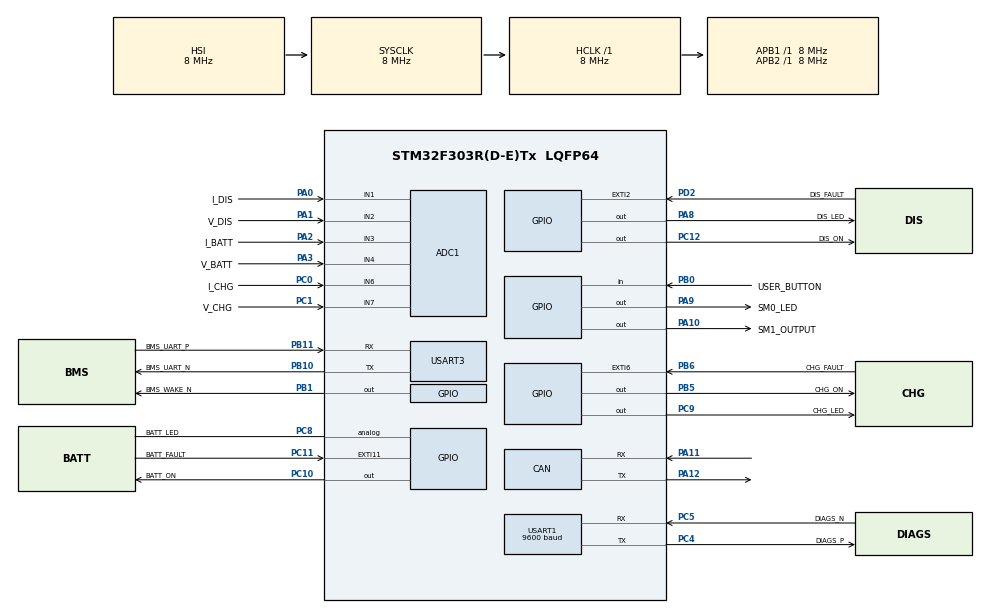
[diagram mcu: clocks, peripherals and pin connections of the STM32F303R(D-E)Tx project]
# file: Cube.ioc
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ADC1.Channel-3\#ChannelRegularConversion=ADC_CHANNEL_1
ADC1.NbrOfConversionFlag=1
ADC1.Offset-3\#ChannelRegularConversion=0
ADC1.OffsetNumber-3\#ChannelRegularConversion=ADC_OFFSET_NONE
ADC1.Rank-3\#ChannelRegularConversion=1
ADC1.SamplingTime-3\#ChannelRegularConversion=ADC_SAMPLETIME_1CYCLE_5
ADC1.master=1
CAN.CalculateTimeQuantum=2000.0
Mcu.Family=STM32F3
Mcu.Name=STM32F303R(D-E)Tx
Mcu.Package=LQFP64
NVIC.PriorityGroup=NVIC_PRIORITYGROUP_4
PA0.GPIO_Label=I_DIS
PA0.Mode=IN1-Single-Ended
PA0.Signal=ADC1_IN1
PA1.GPIO_Label=V_DIS
PA1.Mode=IN2-Single-Ended
PA1.Signal=ADC1_IN2
PA10.GPIO_Label=SM1_OUTPUT
PA10.Signal=GPIO_Output
PA11.Mode=Master
PA11.Signal=CAN_RX
PA12.Mode=Master
PA12.Signal=CAN_TX
PA13.Mode=JTAG_5_pins
PA13.Signal=SYS_JTMS-SWDIO
PA14.Mode=JTAG_5_pins
PA14.Signal=SYS_JTCK-SWCLK
PA15.Mode=JTAG_5_pins
PA15.Signal=SYS_JTDI
PA2.GPIO_Label=I_BATT
PA2.Mode=IN3-Single-Ended
PA2.Signal=ADC1_IN3
PA3.GPIO_Label=V_BATT
PA3.Mode=IN4-Single-Ended
PA3.Signal=ADC1_IN4
PA8.GPIO_Label=DIS_LED
PA8.Signal=GPIO_Output
PA9.GPIO_Label=SM0_LED
PA9.Signal=GPIO_Output
PB0.GPIO_Label=USER_BUTTON
PB0.Signal=GPIO_Input
PB1.GPIO_Label=BMS_WAKE_N
PB1.Signal=GPIO_Output
PB10.GPIO_Label=BMS_UART_N
PB10.Mode=Asynchronous
PB10.Signal=USART3_TX
PB11.GPIO_Label=BMS_UART_P
PB11.Mode=Asynchronous
PB11.Signal=USART3_RX
PB3.Mode=JTAG_5_pins
PB3.Signal=SYS_JTDO-TRACESWO
PB4.Mode=JTAG_5_pins
PB4.Signal=SYS_NJTRST
PB5.GPIO_Label=CHG_ON
PB5.Signal=GPIO_Output
PB6.GPIO_Label=CHG_FAULT
PB6.Signal=GPXTI6
PC0.GPIO_Label=I_CHG
PC0.Signal=ADCx_IN6
PC1.GPIO_Label=V_CHG
PC1.Signal=ADCx_IN7
PC10.GPIO_Label=BATT_ON
PC10.Signal=GPIO_Output
PC11.GPIO_Label=BATT_FAULT
PC11.Signal=GPXTI11
PC12.GPIO_Label=DIS_ON
PC12.Signal=GPIO_Output
PC14-OSC32_IN.Mode=LSE-External-Oscillator
PC14-OSC32_IN.Signal=RCC_OSC32_IN
PC15-OSC32_OUT.Mode=LSE-External-Oscillator
PC15-OSC32_OUT.Signal=RCC_OSC32_OUT
PC4.GPIO_Label=DIAGS_P
PC4.Mode=Asynchronous
PC4.Signal=USART1_TX
PC5.GPIO_Label=DIAGS_N
PC5.Mode=Asynchronous
PC5.Signal=USART1_RX
PC8.GPIO_Label=BATT_LED
PC8.Signal=GPIO_Analog
PC9.GPIO_Label=CHG_LED
PC9.Signal=GPIO_Output
PD2.GPIO_Label=DIS_FAULT
PD2.Signal=GPXTI2
PF0-OSC_IN.Mode=HSE-External-Oscillator
PF0-OSC_IN.Signal=RCC_OSC_IN
PF1-OSC_OUT.Mode=HSE-External-Oscillator
PF1-OSC_OUT.Signal=RCC_OSC_OUT
ProjectManager.HeapSize=0x200
ProjectManager.StackSize=0x400
ProjectManager.TargetToolchain=SW4STM32
RCC.AHBFreq_Value=8000000
RCC.APB1Freq_Value=8000000
RCC.APB2Freq_Value=8000000
RCC.CortexFreq_Value=8000000
RCC.HSE_VALUE=16000000
RCC.HSI_VALUE=8000000
RCC.SYSCLKFreq_VALUE=8000000
RCC.USBFreq_Value=16000000
SH.ADCx_IN6.0=ADC1_IN6,IN6-Single-Ended
SH.ADCx_IN7.0=ADC1_IN7,IN7-Single-Ended
USART1.BaudRate=9600
USART1.VirtualMode-Asynchronous=VM_ASYNC
USART3.VirtualMode-Asynchronous=VM_ASYNC
board=custom

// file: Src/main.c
/* USER CODE BEGIN Header */
/**
  ******************************************************************************
  * @file           : main.c
  * @brief          : Main program body
  ******************************************************************************
  * @attention
  *
  * <h2><center>&copy; Copyright (c) 2020 STMicroelectronics.
  * All rights reserved.</center></h2>
  *
  * This software component is licensed by ST under BSD 3-Clause license,
  * the "License"; You may not use this file except in compliance with the
  * License. You may obtain a copy of the License at:
  *                        opensource.org/licenses/BSD-3-Clause
  *
  ******************************************************************************
  */
/* USER CODE END Header */

#include "main.h"

ADC_HandleTypeDef hadc1;

CAN_HandleTypeDef hcan;

UART_HandleTypeDef huart1;
UART_HandleTypeDef huart3;

void SystemClock_Config(void);
static void MX_GPIO_Init(void);
static void MX_CAN_Init(void);
static void MX_USART1_UART_Init(void);
static void MX_USART3_UART_Init(void);
static void MX_ADC1_Init(void);

int main(void)
{

  /* MCU Configuration--------------------------------------------------------*/

  /* Reset of all peripherals, Initializes the Flash interface and the Systick. */
  HAL_Init();

  /* Configure the system clock */
  SystemClock_Config();

  /* Initialize all configured peripherals */
  MX_GPIO_Init();
  MX_CAN_Init();
  MX_USART1_UART_Init();
  MX_USART3_UART_Init();
  MX_ADC1_Init();

  /* USER CODE BEGIN 2 */
  diagsUARTInit(&huart1);

  /* USER CODE END 2 */

  /* Infinite loop */
  /* USER CODE BEGIN WHILE */
  while (1)
  {
    //HAL_GPIO_TogglePin(GPIOC, CHG_LED_Pin);
    //HAL_GPIO_TogglePin(GPIOA, SM0_LED_Pin);
    //HAL_GPIO_TogglePin(GPIOA, SM1_OUTPUT_Pin);
	debugToggleLED(GPIOA, SM0_LED_Pin);
	debugPrintLine("tiddies");
    HAL_Delay(1400);
  }
  /* USER CODE END 3 */
}

void SystemClock_Config(void)
{
  RCC_OscInitTypeDef RCC_OscInitStruct = {0};
  RCC_ClkInitTypeDef RCC_ClkInitStruct = {0};
  RCC_PeriphCLKInitTypeDef PeriphClkInit = {0};

  /** Initializes the CPU, AHB and APB busses clocks
  */
  RCC_OscInitStruct.OscillatorType = RCC_OSCILLATORTYPE_HSI;
  RCC_OscInitStruct.HSIState = RCC_HSI_ON;
  RCC_OscInitStruct.HSICalibrationValue = RCC_HSICALIBRATION_DEFAULT;
  RCC_OscInitStruct.PLL.PLLState = RCC_PLL_ON;
  RCC_OscInitStruct.PLL.PLLSource = RCC_PLLSOURCE_HSI;
  RCC_OscInitStruct.PLL.PLLMUL = RCC_PLL_MUL2;
  RCC_OscInitStruct.PLL.PREDIV = RCC_PREDIV_DIV1;
  if (HAL_RCC_OscConfig(&RCC_OscInitStruct) != HAL_OK)
  {
    Error_Handler();
  }
  /** Initializes the CPU, AHB and APB busses clocks
  */
  RCC_ClkInitStruct.ClockType = RCC_CLOCKTYPE_HCLK|RCC_CLOCKTYPE_SYSCLK
                              |RCC_CLOCKTYPE_PCLK1|RCC_CLOCKTYPE_PCLK2;
  RCC_ClkInitStruct.SYSCLKSource = RCC_SYSCLKSOURCE_HSI;
  RCC_ClkInitStruct.AHBCLKDivider = RCC_SYSCLK_DIV1;
  RCC_ClkInitStruct.APB1CLKDivider = RCC_HCLK_DIV1;
  RCC_ClkInitStruct.APB2CLKDivider = RCC_HCLK_DIV1;

  if (HAL_RCC_ClockConfig(&RCC_ClkInitStruct, FLASH_LATENCY_0) != HAL_OK)
  {
    Error_Handler();
  }
  PeriphClkInit.PeriphClockSelection = RCC_PERIPHCLK_USART1|RCC_PERIPHCLK_USART3
                              |RCC_PERIPHCLK_ADC12;
  PeriphClkInit.Usart1ClockSelection = RCC_USART1CLKSOURCE_PCLK2;
  PeriphClkInit.Usart3ClockSelection = RCC_USART3CLKSOURCE_PCLK1;
  PeriphClkInit.Adc12ClockSelection = RCC_ADC12PLLCLK_DIV1;
  if (HAL_RCCEx_PeriphCLKConfig(&PeriphClkInit) != HAL_OK)
  {
    Error_Handler();
  }
}

static void MX_ADC1_Init(void)
{

  ADC_MultiModeTypeDef multimode = {0};
  ADC_ChannelConfTypeDef sConfig = {0};

  /** Common config
  */
  hadc1.Instance = ADC1;
  hadc1.Init.ClockPrescaler = ADC_CLOCK_ASYNC_DIV1;
  hadc1.Init.Resolution = ADC_RESOLUTION_12B;
  hadc1.Init.ScanConvMode = ADC_SCAN_DISABLE;
  hadc1.Init.ContinuousConvMode = DISABLE;
  hadc1.Init.DiscontinuousConvMode = DISABLE;
  hadc1.Init.ExternalTrigConvEdge = ADC_EXTERNALTRIGCONVEDGE_NONE;
  hadc1.Init.ExternalTrigConv = ADC_SOFTWARE_START;
  hadc1.Init.DataAlign = ADC_DATAALIGN_RIGHT;
  hadc1.Init.NbrOfConversion = 1;
  hadc1.Init.DMAContinuousRequests = DISABLE;
  hadc1.Init.EOCSelection = ADC_EOC_SINGLE_CONV;
  hadc1.Init.LowPowerAutoWait = DISABLE;
  hadc1.Init.Overrun = ADC_OVR_DATA_OVERWRITTEN;
  if (HAL_ADC_Init(&hadc1) != HAL_OK)
  {
    Error_Handler();
  }
  /** Configure the ADC multi-mode
  */
  multimode.Mode = ADC_MODE_INDEPENDENT;
  if (HAL_ADCEx_MultiModeConfigChannel(&hadc1, &multimode) != HAL_OK)
  {
    Error_Handler();
  }
  /** Configure Regular Channel
  */
  sConfig.Channel = ADC_CHANNEL_1;
  sConfig.Rank = ADC_REGULAR_RANK_1;
  sConfig.SingleDiff = ADC_SINGLE_ENDED;
  sConfig.SamplingTime = ADC_SAMPLETIME_1CYCLE_5;
  sConfig.OffsetNumber = ADC_OFFSET_NONE;
  sConfig.Offset = 0;
  if (HAL_ADC_ConfigChannel(&hadc1, &sConfig) != HAL_OK)
  {
    Error_Handler();
  }

}

static void MX_CAN_Init(void)
{

  hcan.Instance = CAN;
  hcan.Init.Prescaler = 16;
  hcan.Init.Mode = CAN_MODE_NORMAL;
  hcan.Init.SyncJumpWidth = CAN_SJW_1TQ;
  hcan.Init.TimeSeg1 = CAN_BS1_1TQ;
  hcan.Init.TimeSeg2 = CAN_BS2_1TQ;
  hcan.Init.TimeTriggeredMode = DISABLE;
  hcan.Init.AutoBusOff = DISABLE;
  hcan.Init.AutoWakeUp = DISABLE;
  hcan.Init.AutoRetransmission = DISABLE;
  hcan.Init.ReceiveFifoLocked = DISABLE;
  hcan.Init.TransmitFifoPriority = DISABLE;
  if (HAL_CAN_Init(&hcan) != HAL_OK)
  {
    Error_Handler();
  }

}

static void MX_USART1_UART_Init(void)
{

  huart1.Instance = USART1;
  huart1.Init.BaudRate = 250000;									// BQ requires 250k baud rate
  huart1.Init.WordLength = UART_WORDLENGTH_8B;						// BQ requires 8 data bits
  huart1.Init.StopBits = UART_STOPBITS_1;							// BQ requires one stop bit
  huart1.Init.Parity = UART_PARITY_NONE;
  huart1.Init.Mode = UART_MODE_TX_RX;
  huart1.Init.HwFlowCtl = UART_HWCONTROL_NONE;
  huart1.Init.OverSampling = UART_OVERSAMPLING_16;
  huart1.Init.OneBitSampling = UART_ONE_BIT_SAMPLE_DISABLE;
  huart1.AdvancedInit.AdvFeatureInit = UART_ADVFEATURE_NO_INIT;
  if (HAL_UART_Init(&huart1) != HAL_OK)
  {
    Error_Handler();
  }

}

static void MX_USART3_UART_Init(void)
{

  huart3.Instance = USART3;
  huart3.Init.BaudRate = 9600;
  huart3.Init.WordLength = UART_WORDLENGTH_8B;
  huart3.Init.StopBits = UART_STOPBITS_1;
  huart3.Init.Parity = UART_PARITY_NONE;
  huart3.Init.Mode = UART_MODE_TX_RX;
  huart3.Init.HwFlowCtl = UART_HWCONTROL_NONE;
  huart3.Init.OverSampling = UART_OVERSAMPLING_16;
  huart3.Init.OneBitSampling = UART_ONE_BIT_SAMPLE_DISABLE;
  huart3.AdvancedInit.AdvFeatureInit = UART_ADVFEATURE_NO_INIT;
  if (HAL_UART_Init(&huart3) != HAL_OK)
  {
    Error_Handler();
  }

}

static void MX_GPIO_Init(void)
{
  GPIO_InitTypeDef GPIO_InitStruct = {0};

  /* GPIO Ports Clock Enable */
  __HAL_RCC_GPIOC_CLK_ENABLE();
  __HAL_RCC_GPIOF_CLK_ENABLE();
  __HAL_RCC_GPIOA_CLK_ENABLE();
  __HAL_RCC_GPIOB_CLK_ENABLE();
  __HAL_RCC_GPIOD_CLK_ENABLE();

  /*Configure GPIO pin Output Level */
  HAL_GPIO_WritePin(GPIOB, BMS_WAKE_N_Pin|CHG_ON_Pin, GPIO_PIN_RESET);

  /*Configure GPIO pin Output Level */
  HAL_GPIO_WritePin(GPIOC, CHG_LED_Pin|BATT_ON_Pin|DIS_ON_Pin, GPIO_PIN_RESET);

  /*Configure GPIO pin Output Level */
  HAL_GPIO_WritePin(GPIOA, DIS_LED_Pin|SM0_LED_Pin|SM1_OUTPUT_Pin, GPIO_PIN_RESET);

  /*Configure GPIO pin : USER_BUTTON_Pin */
  GPIO_InitStruct.Pin = USER_BUTTON_Pin;
  GPIO_InitStruct.Mode = GPIO_MODE_INPUT;
  GPIO_InitStruct.Pull = GPIO_NOPULL;
  HAL_GPIO_Init(USER_BUTTON_GPIO_Port, &GPIO_InitStruct);

  /*Configure GPIO pins : BMS_WAKE_N_Pin CHG_ON_Pin */
  GPIO_InitStruct.Pin = BMS_WAKE_N_Pin|CHG_ON_Pin;
  GPIO_InitStruct.Mode = GPIO_MODE_OUTPUT_PP;
  GPIO_InitStruct.Pull = GPIO_NOPULL;
  GPIO_InitStruct.Speed = GPIO_SPEED_FREQ_LOW;
  HAL_GPIO_Init(GPIOB, &GPIO_InitStruct);

  /*Configure GPIO pin : BATT_LED_Pin */
  GPIO_InitStruct.Pin = BATT_LED_Pin;
  GPIO_InitStruct.Mode = GPIO_MODE_ANALOG;
  GPIO_InitStruct.Pull = GPIO_NOPULL;
  HAL_GPIO_Init(BATT_LED_GPIO_Port, &GPIO_InitStruct);

  /*Configure GPIO pins : CHG_LED_Pin BATT_ON_Pin DIS_ON_Pin */
  GPIO_InitStruct.Pin = CHG_LED_Pin|BATT_ON_Pin|DIS_ON_Pin;
  GPIO_InitStruct.Mode = GPIO_MODE_OUTPUT_PP;
  GPIO_InitStruct.Pull = GPIO_NOPULL;
  GPIO_InitStruct.Speed = GPIO_SPEED_FREQ_LOW;
  HAL_GPIO_Init(GPIOC, &GPIO_InitStruct);

  /*Configure GPIO pins : DIS_LED_Pin SM0_LED_Pin SM1_OUTPUT_Pin */
  GPIO_InitStruct.Pin = DIS_LED_Pin|SM0_LED_Pin|SM1_OUTPUT_Pin;
  GPIO_InitStruct.Mode = GPIO_MODE_OUTPUT_PP;
  GPIO_InitStruct.Pull = GPIO_NOPULL;
  GPIO_InitStruct.Speed = GPIO_SPEED_FREQ_LOW;
  HAL_GPIO_Init(GPIOA, &GPIO_InitStruct);

  /*Configure GPIO pin : BATT_FAULT_Pin */
  GPIO_InitStruct.Pin = BATT_FAULT_Pin;
  GPIO_InitStruct.Mode = GPIO_MODE_IT_RISING;
  GPIO_InitStruct.Pull = GPIO_NOPULL;
  HAL_GPIO_Init(BATT_FAULT_GPIO_Port, &GPIO_InitStruct);

  /*Configure GPIO pin : DIS_FAULT_Pin */
  GPIO_InitStruct.Pin = DIS_FAULT_Pin;
  GPIO_InitStruct.Mode = GPIO_MODE_IT_RISING;
  GPIO_InitStruct.Pull = GPIO_NOPULL;
  HAL_GPIO_Init(DIS_FAULT_GPIO_Port, &GPIO_InitStruct);

  /*Configure GPIO pin : CHG_FAULT_Pin */
  GPIO_InitStruct.Pin = CHG_FAULT_Pin;
  GPIO_InitStruct.Mode = GPIO_MODE_IT_RISING;
  GPIO_InitStruct.Pull = GPIO_NOPULL;
  HAL_GPIO_Init(CHG_FAULT_GPIO_Port, &GPIO_InitStruct);

}

void Error_Handler(void)
{
}

/************************ (C) COPYRIGHT STMicroelectronics *****END OF FILE****/
